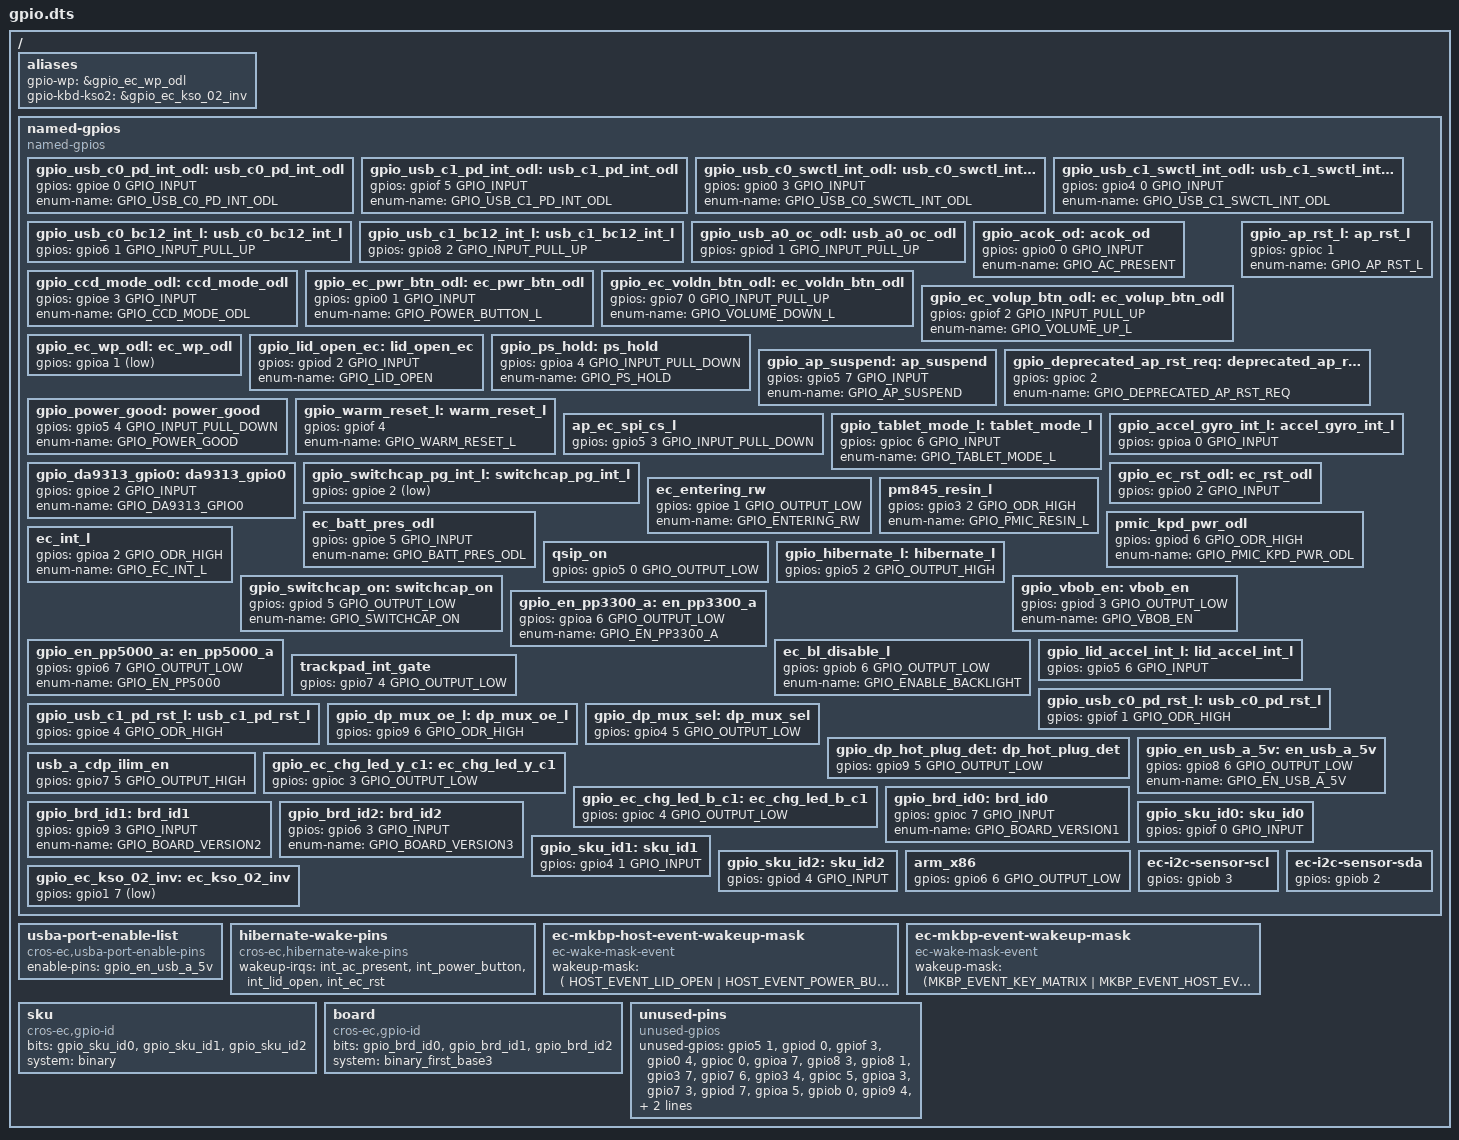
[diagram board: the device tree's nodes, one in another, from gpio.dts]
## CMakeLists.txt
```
# Copyright 2021 The ChromiumOS Authors
# Use of this source code is governed by a BSD-style license that can be
# found in the LICENSE file.

cmake_minimum_required(VERSION 3.13.1)

find_package(Zephyr REQUIRED HINTS "${ZEPHYR_BASE}")
project(lazor)

cros_ec_library_include_directories(include)

zephyr_library_sources_ifdef(CONFIG_PLATFORM_EC_USBC
  "src/power.c"
  "src/usb_pd_policy.c"
  "src/usbc_config.c")

zephyr_library_sources(
  "src/sku.c"
  "src/switchcap.c")

# Board specific implementation
zephyr_library_sources_ifdef(CONFIG_PLATFORM_EC_I2C
  "src/i2c.c")
```

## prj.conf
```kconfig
# Copyright 2021 The Chromium OS Authors. All rights reserved.
# Use of this source code is governed by a BSD-style license that can be
# found in the LICENSE file.

CONFIG_CROS_EC=y
#
# Lazor actually has a NPCX7M6FC, but
# the NPCX7M7FC is actually the same die, without the
# extra RAM being tested. The code size really could
# do with the extra space, so we pretend the EC is the
# part with the larger RAM. YMMV.
#
CONFIG_SOC_NPCX7M7FC=y
CONFIG_SOC_SERIES_NPCX7=y
CONFIG_SHIMMED_TASKS=y
CONFIG_PLATFORM_EC=y
CONFIG_PLATFORM_EC_BRINGUP=y
CONFIG_PLATFORM_EC_EXTPOWER_GPIO=y
CONFIG_PLATFORM_EC_SWITCH=y
CONFIG_PLATFORM_EC_LID_SWITCH=y
CONFIG_PLATFORM_EC_BACKLIGHT_LID=y
CONFIG_PLATFORM_EC_POWER_BUTTON=y

# I2C
CONFIG_I2C=y

# LED
CONFIG_PLATFORM_EC_LED_DT=y

# PWM
CONFIG_PWM=y
CONFIG_PWM_SHELL=n

# Application Processor is Qualcomm SC7180
CONFIG_AP_ARM_QUALCOMM_SC7180=y

# Board version is selected over GPIO board ID pins.
CONFIG_PLATFORM_EC_BOARD_VERSION_GPIO=y

# LN9310 Switchcap
CONFIG_PLATFORM_EC_SWITCHCAP_LN9310=y

# Power Sequencing
CONFIG_PLATFORM_EC_POWERSEQ=y
CONFIG_PLATFORM_EC_POWERSEQ_HOST_SLEEP=y
CONFIG_PLATFORM_EC_POWER_SLEEP_FAILURE_DETECTION=y
CONFIG_PLATFORM_EC_CHIPSET_RESET_HOOK=y
CONFIG_PLATFORM_EC_CHIPSET_RESUME_INIT_HOOK=y

# Trogdor family does not use EFS2
CONFIG_PLATFORM_EC_VBOOT_EFS2=n

# MKBP event
CONFIG_PLATFORM_EC_MKBP_EVENT=y
CONFIG_PLATFORM_EC_MKBP_USE_GPIO=y

# Keyboard
CONFIG_PLATFORM_EC_KEYBOARD=y
CONFIG_PLATFORM_EC_KEYBOARD_PROTOCOL_MKBP=y
CONFIG_PLATFORM_EC_MKBP_INPUT_DEVICES=y
CONFIG_PLATFORM_EC_KEYBOARD_COL2_INVERTED=y
CONFIG_PLATFORM_EC_VOLUME_BUTTONS=y
CONFIG_PLATFORM_EC_CMD_BUTTON=y
CONFIG_CROS_KB_RAW_NPCX=y

# ADC
CONFIG_ADC=y
CONFIG_ADC_SHELL=n

# Battery
CONFIG_PLATFORM_EC_BATTERY=y
CONFIG_PLATFORM_EC_BATTERY_SMART=y
CONFIG_PLATFORM_EC_I2C_VIRTUAL_BATTERY=y
CONFIG_PLATFORM_EC_I2C_PASSTHRU_RESTRICTED=y
CONFIG_PLATFORM_EC_BATTERY_FUEL_GAUGE=y
CONFIG_PLATFORM_EC_BATTERY_CUT_OFF=y
CONFIG_PLATFORM_EC_BATTERY_PRESENT_GPIO=y
CONFIG_PLATFORM_EC_CHARGER_ISL9238=y
CONFIG_PLATFORM_EC_CHARGE_RAMP_HW=y
CONFIG_PLATFORM_EC_USE_BATTERY_DEVICE_CHEMISTRY=y
CONFIG_PLATFORM_EC_BATTERY_DEVICE_CHEMISTRY="LION"
CONFIG_PLATFORM_EC_BATTERY_REVIVE_DISCONNECT=y
CONFIG_PLATFORM_EC_CHARGER_DISCHARGE_ON_AC=y
CONFIG_PLATFORM_EC_CHARGER_DISCHARGE_ON_AC_CHARGER=y
CONFIG_PLATFORM_EC_CHARGER_MIN_BAT_PCT_FOR_POWER_ON=2
CONFIG_PLATFORM_EC_CHARGER_MIN_POWER_MW_FOR_POWER_ON=10000
CONFIG_PLATFORM_EC_CHARGER_PROFILE_OVERRIDE=y
CONFIG_PLATFORM_EC_CHARGER_PSYS=y
CONFIG_PLATFORM_EC_CHARGER_PSYS_READ=y
CONFIG_PLATFORM_EC_CHARGER_SENSE_RESISTOR=10
CONFIG_PLATFORM_EC_CHARGER_SENSE_RESISTOR_AC=20
CONFIG_PLATFORM_EC_CONSOLE_CMD_CHARGER_ADC_AMON_BMON=y

# USB-A
CONFIG_PLATFORM_EC_USBA=y

# USB-C
CONFIG_PLATFORM_EC_BC12_DETECT_PI3USB9201=y
CONFIG_PLATFORM_EC_USB_PD_USB32_DRD=n
CONFIG_PLATFORM_EC_USBC_PPC_SN5S330=y
CONFIG_PLATFORM_EC_USBC_RETIMER_FW_UPDATE=n
CONFIG_PLATFORM_EC_USBC_SS_MUX_DFP_ONLY=y
CONFIG_PLATFORM_EC_USB_DRP_ACC_TRYSRC=y
CONFIG_PLATFORM_EC_USB_PD_5V_EN_CUSTOM=y
CONFIG_PLATFORM_EC_USB_PD_VBUS_DETECT_TCPC=y
CONFIG_PLATFORM_EC_USB_PD_DISCHARGE_PPC=y
CONFIG_PLATFORM_EC_USB_PD_REV30=n
CONFIG_PLATFORM_EC_USB_PD_TBT_COMPAT_MODE=n
CONFIG_PLATFORM_EC_USB_PD_USB4=n
CONFIG_PLATFORM_EC_USB_PD_TCPC_LOW_POWER=y
CONFIG_PLATFORM_EC_USB_PD_TCPM_MULTI_PS8XXX=y
CONFIG_PLATFORM_EC_USB_PD_TCPM_PS8751=y
CONFIG_PLATFORM_EC_USB_PD_TCPM_PS8805=y
CONFIG_PLATFORM_EC_USB_PD_TCPC_RUNTIME_CONFIG=n
CONFIG_PLATFORM_EC_USB_MUX_RUNTIME_CONFIG=n
CONFIG_PLATFORM_EC_USB_PD_LOGGING=y

# USB ID
# This is allocated specifically for Trogdor
# http://google3/hardware/standards/usb/
# TODO(b/183608112): Move to device tree
CONFIG_PLATFORM_EC_USB_PID=0x5043

# RTC
CONFIG_PLATFORM_EC_RTC=y
CONFIG_CROS_RTC_NPCX=y
CONFIG_PLATFORM_EC_HOSTCMD_RTC=y
CONFIG_PLATFORM_EC_CONSOLE_CMD_RTC=y

# EC software sync
CONFIG_PLATFORM_EC_VBOOT_HASH=y

# Sensors
CONFIG_PLATFORM_EC_MOTIONSENSE=y
CONFIG_PLATFORM_EC_ACCEL_FIFO=y
CONFIG_PLATFORM_EC_CONSOLE_CMD_ACCELS=y
CONFIG_PLATFORM_EC_CONSOLE_CMD_ACCEL_INFO=y
CONFIG_PLATFORM_EC_GMR_TABLET_MODE=y
CONFIG_PLATFORM_EC_LID_ANGLE=y
CONFIG_PLATFORM_EC_LID_ANGLE_UPDATE=y
CONFIG_PLATFORM_EC_SENSOR_TIGHT_TIMESTAMPS=y
CONFIG_PLATFORM_EC_TABLET_MODE=y
CONFIG_PLATFORM_EC_TABLET_MODE_SWITCH=y

# Sensor Drivers
CONFIG_PLATFORM_EC_ACCEL_BMA255=y
CONFIG_PLATFORM_EC_ACCELGYRO_BMI160=y
CONFIG_PLATFORM_EC_ACCELGYRO_BMI_COMM_I2C=y

# Console history
CONFIG_SHELL_HISTORY=y
CONFIG_SHELL_CMDS=y
CONFIG_SHELL_HELP=n
CONFIG_SHELL_MINIMAL=y

# Taskinfo
CONFIG_THREAD_MONITOR=y
CONFIG_KERNEL_SHELL=y

CONFIG_SYSCON=y

# Features should be enabled. But the code RAM is not enough, disable them.
#CONFIG_PLATFORM_EC_ACCEL_SPOOF_MODE=y
#CONFIG_PLATFORM_EC_EMULATED_SYSRQ=y
```

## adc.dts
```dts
/* Copyright 2022 The ChromiumOS Authors
 * Use of this source code is governed by a BSD-style license that can be
 * found in the LICENSE file.
 */

#include <zephyr/dt-bindings/adc/adc.h>

/ {
	named-adc-channels {
		compatible = "named-adc-channels";

		vbus {
			enum-name = "ADC_VBUS";
			io-channels = <&adc0 1>;
			/* Measure VBUS through a 1/10 voltage divider */
			mul = <10>;
		};
		amon_bmon {
			enum-name = "ADC_AMON_BMON";
			io-channels = <&adc0 2>;
			/*
			 * Adapter current output or battery charging/
			 * discharging current (uV) 18x amplification on
			 * charger side.
			 */
			mul = <1000>;
			div = <18>;
		};
		psys {
			enum-name = "ADC_PSYS";
			io-channels = <&adc0 3>;
			/*
			 * ISL9238 PSYS output is 1.44 uA/W over 5.6K resistor,
			 * to read 0.8V @ 99 W, i.e. 124000 uW/mV.
			 */
			mul = <124000>;
		};
	};

};

&adc0 {
	status = "okay";
	pinctrl-0 = <&adc0_chan1_gp44
		     &adc0_chan2_gp43
		     &adc0_chan3_gp42>;
	pinctrl-names = "default";
};
```

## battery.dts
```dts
/* Copyright 2021 The ChromiumOS Authors
 * Use of this source code is governed by a BSD-style license that can be
 * found in the LICENSE file.
 */

/ {
	batteries {
		default_battery: ap16l5j {
			compatible = "panasonic,ap16l5j", "battery-smart";
		};
		ap16l5j_009 {
			compatible = "panasonic,ap16l5j-009", "battery-smart";
		};
		ap16l8j {
			compatible = "lgc,ap16l8j", "battery-smart";
		};
		lgc_ap18c8k {
			compatible = "lgc,ap18c8k", "battery-smart";
		};
		murata_ap18c4k {
			compatible = "murata,ap18c4k", "battery-smart";
		};
	};
};
```

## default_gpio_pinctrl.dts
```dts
/* Copyright 2022 The ChromiumOS Authors
 * Use of this source code is governed by a BSD-style license that can be
 * found in the LICENSE file.
 */

/* Adds the &alt1_no_lpc_espi setting over the NPCX7 default setting. */
&{/def-io-conf-list} {
	pinmux = <&alt0_gpio_no_spip
		  &alt0_gpio_no_fpip
		  &alt1_no_pwrgd
		  &alt1_no_lpc_espi
		  &alta_no_peci_en
		  &altd_npsl_in1_sl
		  &altd_npsl_in2_sl
		  &altd_psl_in3_sl
		  &altd_psl_in4_sl
		  &alt7_no_ksi0_sl
		  &alt7_no_ksi1_sl
		  &alt7_no_ksi2_sl
		  &alt7_no_ksi3_sl
		  &alt7_no_ksi4_sl
		  &alt7_no_ksi5_sl
		  &alt7_no_ksi6_sl
		  &alt7_no_ksi7_sl
		  &alt8_no_kso00_sl
		  &alt8_no_kso01_sl
		  &alt8_no_kso02_sl
		  &alt8_no_kso03_sl
		  &alt8_no_kso04_sl
		  &alt8_no_kso05_sl
		  &alt8_no_kso06_sl
		  &alt8_no_kso07_sl
		  &alt9_no_kso08_sl
		  &alt9_no_kso09_sl
		  &alt9_no_kso10_sl
		  &alt9_no_kso11_sl
		  &alt9_no_kso12_sl
		  &alt9_no_kso13_sl
		  &alt9_no_kso14_sl
		  &alt9_no_kso15_sl
		  &alta_no_kso16_sl
		  &alta_no_kso17_sl >;
};
```

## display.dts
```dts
/* Copyright 2022 The Chromium OS Authors. All rights reserved.
 * Use of this source code is governed by a BSD-style license that can be
 * found in the LICENSE file.
 */

/ {
	displight {
		compatible = "cros-ec,displight";
		pwms = <&pwm5 0 PWM_HZ(4800) PWM_POLARITY_NORMAL>;
		generic-pwm-channel = <1>;
	};
};

&pwm5 {
	status = "okay";
	pinctrl-0 = <&pwm5_gpb7>;
	pinctrl-names = "default";
};
```

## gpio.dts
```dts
/* Copyright 2021 The Chromium OS Authors. All rights reserved.
 * Use of this source code is governed by a BSD-style license that can be
 * found in the LICENSE file.
 */

#include <dt-bindings/wake_mask_event_defines.h>

/ {
	aliases {
		gpio-wp = &gpio_ec_wp_odl;
		gpio-kbd-kso2 = &gpio_ec_kso_02_inv;
	};

	named-gpios {
		compatible = "named-gpios";

		gpio_usb_c0_pd_int_odl: usb_c0_pd_int_odl {
			gpios = <&gpioe 0 GPIO_INPUT>;
			enum-name = "GPIO_USB_C0_PD_INT_ODL";
		};
		gpio_usb_c1_pd_int_odl: usb_c1_pd_int_odl {
			gpios = <&gpiof 5 GPIO_INPUT>;
			enum-name = "GPIO_USB_C1_PD_INT_ODL";
		};
		gpio_usb_c0_swctl_int_odl: usb_c0_swctl_int_odl {
			gpios = <&gpio0 3 GPIO_INPUT>;
			enum-name = "GPIO_USB_C0_SWCTL_INT_ODL";
		};
		gpio_usb_c1_swctl_int_odl: usb_c1_swctl_int_odl {
			gpios = <&gpio4 0 GPIO_INPUT>;
			enum-name = "GPIO_USB_C1_SWCTL_INT_ODL";
		};
		gpio_usb_c0_bc12_int_l: usb_c0_bc12_int_l {
			gpios = <&gpio6 1 GPIO_INPUT_PULL_UP>;
		};
		gpio_usb_c1_bc12_int_l: usb_c1_bc12_int_l {
			gpios = <&gpio8 2 GPIO_INPUT_PULL_UP>;
		};
		gpio_usb_a0_oc_odl: usb_a0_oc_odl {
			gpios = <&gpiod 1 GPIO_INPUT_PULL_UP>;
		};
		gpio_acok_od: acok_od {
			gpios = <&gpio0 0 GPIO_INPUT>;
			enum-name = "GPIO_AC_PRESENT";
		};
		gpio_ccd_mode_odl: ccd_mode_odl {
			gpios = <&gpioe 3 GPIO_INPUT>;
			enum-name = "GPIO_CCD_MODE_ODL";
		};
		gpio_ec_pwr_btn_odl: ec_pwr_btn_odl {
			gpios = <&gpio0 1 GPIO_INPUT>;
			enum-name = "GPIO_POWER_BUTTON_L";
		};
		gpio_ec_voldn_btn_odl: ec_voldn_btn_odl {
			gpios = <&gpio7 0 GPIO_INPUT_PULL_UP>;
			enum-name = "GPIO_VOLUME_DOWN_L";
		};
		gpio_ec_volup_btn_odl: ec_volup_btn_odl {
			gpios = <&gpiof 2 GPIO_INPUT_PULL_UP>;
			enum-name = "GPIO_VOLUME_UP_L";
		};
		gpio_ec_wp_odl: ec_wp_odl {
			gpios = <&gpioa 1 (GPIO_INPUT | GPIO_ACTIVE_LOW)>;
		};
		gpio_lid_open_ec: lid_open_ec {
			gpios = <&gpiod 2 GPIO_INPUT>;
			enum-name = "GPIO_LID_OPEN";
		};
		gpio_ap_rst_l: ap_rst_l {
			gpios = <&gpioc 1 (GPIO_INPUT | GPIO_VOLTAGE_1P8)>;
			enum-name = "GPIO_AP_RST_L";
		};
		gpio_ps_hold: ps_hold {
			gpios = <&gpioa 4 GPIO_INPUT_PULL_DOWN>;
			enum-name = "GPIO_PS_HOLD";
		};
		gpio_ap_suspend: ap_suspend {
			gpios = <&gpio5 7 GPIO_INPUT>;
			enum-name = "GPIO_AP_SUSPEND";
		};
		gpio_deprecated_ap_rst_req: deprecated_ap_rst_req {
			gpios = <&gpioc 2 (GPIO_INPUT_PULL_DOWN | GPIO_VOLTAGE_1P8)>;
			enum-name = "GPIO_DEPRECATED_AP_RST_REQ";
		};
		gpio_power_good: power_good {
			gpios = <&gpio5 4 GPIO_INPUT_PULL_DOWN>;
			enum-name = "GPIO_POWER_GOOD";
		};
		gpio_warm_reset_l: warm_reset_l {
			gpios = <&gpiof 4 (GPIO_INPUT | GPIO_VOLTAGE_1P8)>;
			enum-name = "GPIO_WARM_RESET_L";
		};
		ap_ec_spi_cs_l {
			gpios = <&gpio5 3 GPIO_INPUT_PULL_DOWN>;
		};
		gpio_tablet_mode_l: tablet_mode_l {
			gpios = <&gpioc 6 GPIO_INPUT>;
			enum-name = "GPIO_TABLET_MODE_L";
		};
		gpio_accel_gyro_int_l: accel_gyro_int_l {
			gpios = <&gpioa 0 GPIO_INPUT>;
		};
		gpio_da9313_gpio0: da9313_gpio0 {
			gpios = <&gpioe 2 GPIO_INPUT>;
			enum-name = "GPIO_DA9313_GPIO0";
		};
		/*
		 * Active low input
		 */
		gpio_switchcap_pg_int_l: switchcap_pg_int_l {
			gpios = <&gpioe 2 (GPIO_ACTIVE_LOW | GPIO_INPUT)>;
		};
		gpio_ec_rst_odl: ec_rst_odl {
			gpios = <&gpio0 2 GPIO_INPUT>;
		};
		ec_entering_rw {
			gpios = <&gpioe 1 GPIO_OUTPUT_LOW>;
			enum-name = "GPIO_ENTERING_RW";
		};
		ec_batt_pres_odl {
			gpios = <&gpioe 5 GPIO_INPUT>;
			enum-name = "GPIO_BATT_PRES_ODL";
		};
		pm845_resin_l {
			gpios = <&gpio3 2 GPIO_ODR_HIGH>;
			enum-name = "GPIO_PMIC_RESIN_L";
		};
		pmic_kpd_pwr_odl {
			gpios = <&gpiod 6 GPIO_ODR_HIGH>;
			enum-name = "GPIO_PMIC_KPD_PWR_ODL";
		};
		ec_int_l {
			gpios = <&gpioa 2 GPIO_ODR_HIGH>;
			enum-name = "GPIO_EC_INT_L";
		};
		qsip_on {
			gpios = <&gpio5 0 GPIO_OUTPUT_LOW>;
		};
		gpio_hibernate_l: hibernate_l {
			gpios = <&gpio5 2 GPIO_OUTPUT_HIGH>;
		};
		gpio_switchcap_on: switchcap_on {
			gpios = <&gpiod 5 GPIO_OUTPUT_LOW>;
			enum-name = "GPIO_SWITCHCAP_ON";
		};
		gpio_vbob_en: vbob_en {
			gpios = <&gpiod 3 GPIO_OUTPUT_LOW>;
			enum-name = "GPIO_VBOB_EN";
		};
		gpio_en_pp3300_a: en_pp3300_a {
			gpios = <&gpioa 6 GPIO_OUTPUT_LOW>;
			enum-name = "GPIO_EN_PP3300_A";
		};
		gpio_en_pp5000_a: en_pp5000_a {
			gpios = <&gpio6 7 GPIO_OUTPUT_LOW>;
			enum-name = "GPIO_EN_PP5000";
		};
		ec_bl_disable_l {
			gpios = <&gpiob 6 GPIO_OUTPUT_LOW>;
			enum-name = "GPIO_ENABLE_BACKLIGHT";
		};
		gpio_lid_accel_int_l: lid_accel_int_l {
			gpios = <&gpio5 6 GPIO_INPUT>;
		};
		trackpad_int_gate {
			gpios = <&gpio7 4 GPIO_OUTPUT_LOW>;
		};
		gpio_usb_c0_pd_rst_l: usb_c0_pd_rst_l {
			gpios = <&gpiof 1 GPIO_ODR_HIGH>;
		};
		gpio_usb_c1_pd_rst_l: usb_c1_pd_rst_l {
			gpios = <&gpioe 4 GPIO_ODR_HIGH>;
		};
		gpio_dp_mux_oe_l: dp_mux_oe_l {
			gpios = <&gpio9 6 GPIO_ODR_HIGH>;
		};
		gpio_dp_mux_sel: dp_mux_sel {
			gpios = <&gpio4 5 GPIO_OUTPUT_LOW>;
		};
		gpio_dp_hot_plug_det: dp_hot_plug_det {
			gpios = <&gpio9 5 GPIO_OUTPUT_LOW>;
		};
		gpio_en_usb_a_5v: en_usb_a_5v {
			gpios = <&gpio8 6 GPIO_OUTPUT_LOW>;
			enum-name = "GPIO_EN_USB_A_5V";
		};
		usb_a_cdp_ilim_en {
			gpios = <&gpio7 5 GPIO_OUTPUT_HIGH>;
		};
		gpio_ec_chg_led_y_c1: ec_chg_led_y_c1 {
			#led-pin-cells = <1>;
			gpios = <&gpioc 3 GPIO_OUTPUT_LOW>;
		};
		gpio_ec_chg_led_b_c1: ec_chg_led_b_c1 {
			#led-pin-cells = <1>;
			gpios = <&gpioc 4 GPIO_OUTPUT_LOW>;
		};
		gpio_brd_id0: brd_id0 {
			gpios = <&gpioc 7 GPIO_INPUT>;
			enum-name = "GPIO_BOARD_VERSION1";
		};
		gpio_brd_id1: brd_id1 {
			gpios = <&gpio9 3 GPIO_INPUT>;
			enum-name = "GPIO_BOARD_VERSION2";
		};
		gpio_brd_id2: brd_id2 {
			gpios = <&gpio6 3 GPIO_INPUT>;
			enum-name = "GPIO_BOARD_VERSION3";
		};
		gpio_sku_id0: sku_id0 {
			gpios = <&gpiof 0 GPIO_INPUT>;
		};
		gpio_sku_id1: sku_id1 {
			gpios = <&gpio4 1 GPIO_INPUT>;
		};
		gpio_sku_id2: sku_id2 {
			gpios = <&gpiod 4 GPIO_INPUT>;
		};
		arm_x86 {
			gpios = <&gpio6 6 GPIO_OUTPUT_LOW>;
		};
		ec-i2c-sensor-scl {
			gpios = <&gpiob 3 (GPIO_INPUT | GPIO_VOLTAGE_1P8)>;
		};
		ec-i2c-sensor-sda {
			gpios = <&gpiob 2 (GPIO_INPUT | GPIO_VOLTAGE_1P8)>;
		};
		gpio_ec_kso_02_inv: ec_kso_02_inv {
			gpios = <&gpio1 7 (GPIO_OUTPUT_LOW | GPIO_ACTIVE_LOW)>;
		};
	};

	usba-port-enable-list {
		compatible = "cros-ec,usba-port-enable-pins";
		enable-pins = <&gpio_en_usb_a_5v>;
	};

	hibernate-wake-pins {
		compatible = "cros-ec,hibernate-wake-pins";
		wakeup-irqs = <
			&int_ac_present
			&int_power_button
			&int_lid_open
			&int_ec_rst
		>;
	};

	ec-mkbp-host-event-wakeup-mask {
		compatible = "ec-wake-mask-event";
		wakeup-mask = <(
			HOST_EVENT_LID_OPEN |
			HOST_EVENT_POWER_BUTTON |
			HOST_EVENT_AC_CONNECTED |
			HOST_EVENT_AC_DISCONNECTED |
			HOST_EVENT_HANG_DETECT |
			HOST_EVENT_RTC |
			HOST_EVENT_MODE_CHANGE |
			HOST_EVENT_DEVICE)>;
	};

	ec-mkbp-event-wakeup-mask {
		compatible = "ec-wake-mask-event";
		wakeup-mask = <(MKBP_EVENT_KEY_MATRIX |
				MKBP_EVENT_HOST_EVENT |
				MKBP_EVENT_SENSOR_FIFO)>;
	};

	sku {
		compatible = "cros-ec,gpio-id";

		bits  = <
			&gpio_sku_id0
			&gpio_sku_id1
			&gpio_sku_id2
		>;

		system = "binary";
	};

	board {
		compatible = "cros-ec,gpio-id";

		bits  = <
			&gpio_brd_id0
			&gpio_brd_id1
			&gpio_brd_id2
		>;

		system = "binary_first_base3";
	};

	unused-pins {
		compatible = "unused-gpios";
		unused-gpios =
			<&gpio5 1 0>,
			<&gpiod 0 0>,
			<&gpiof 3 0>,
			<&gpio0 4 0>,
			<&gpioc 0 0>,
			<&gpioa 7 0>,
			<&gpio8 3 0>,
			<&gpio8 1 0>,
			<&gpio3 7 0>,
			<&gpio7 6 0>,
			<&gpio3 4 0>,
			<&gpioc 5 0>,
			<&gpioa 3 0>,
			<&gpio7 3 0>,
			<&gpiod 7 0>,
			<&gpioa 5 0>,
			<&gpiob 0 0>,
			<&gpio9 4 0>,
			<&gpiob 1 0>,
			<&gpio6 2 0>,
			<&gpio3 5 0>,
			<&gpio9 7 0>,
			<&gpio6 0 0>,
			<&gpio7 2 0>;
	};
};
```

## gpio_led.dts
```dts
/* Copyright 2022 The ChromiumOS Authors
 * Use of this source code is governed by a BSD-style license that can be
 * found in the LICENSE file.
 */

/ {
	gpio-led-pins {
		compatible = "cros-ec,gpio-led-pins";

		color_off: color-off {
			led-color = "LED_OFF";
			led-id = "EC_LED_ID_BATTERY_LED";
			led-pins = <&gpio_ec_chg_led_y_c1 0>,
				   <&gpio_ec_chg_led_b_c1 0>;
		};

		color_amber: color-amber {
			led-color = "LED_AMBER";
			led-id = "EC_LED_ID_BATTERY_LED";
			br-color = "EC_LED_COLOR_AMBER";
			led-pins = <&gpio_ec_chg_led_y_c1 1>,
				   <&gpio_ec_chg_led_b_c1 0>;
		};

		color_blue: color-blue {
			led-color = "LED_BLUE";
			led-id = "EC_LED_ID_BATTERY_LED";
			br-color = "EC_LED_COLOR_BLUE";
			led-pins = <&gpio_ec_chg_led_y_c1 0>,
				   <&gpio_ec_chg_led_b_c1 1>;
		};
	};
};
```

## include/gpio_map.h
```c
/* Copyright 2021 The Chromium OS Authors. All rights reserved.
 * Use of this source code is governed by a BSD-style license that can be
 * found in the LICENSE file.
 */

#ifndef __ZEPHYR_GPIO_MAP_H
#define __ZEPHYR_GPIO_MAP_H

#include <devicetree.h>
#include <gpio_signal.h>

/*
 * Set EC_CROS_GPIO_INTERRUPTS to a space-separated list of GPIO_INT items.
 *
 * Each GPIO_INT requires three parameters:
 *   gpio_signal - The enum gpio_signal for the interrupt gpio
 *   interrupt_flags - The interrupt-related flags (e.g. GPIO_INT_EDGE_BOTH)
 *   handler - The platform/ec interrupt handler.
 *
 * Ensure that this files includes all necessary headers to declare all
 * referenced handler functions.
 *
 * For example, one could use the follow definition:
 * #define EC_CROS_GPIO_INTERRUPTS \
 *   GPIO_INT(NAMED_GPIO(h1_ec_pwr_btn_odl), GPIO_INT_EDGE_BOTH, button_print)
 */
#define EC_CROS_GPIO_INTERRUPTS                                               \
	GPIO_INT(GPIO_AC_PRESENT, GPIO_INT_EDGE_BOTH, extpower_interrupt)     \
	GPIO_INT(GPIO_LID_OPEN, GPIO_INT_EDGE_BOTH, lid_interrupt)            \
	GPIO_INT(GPIO_WP_L, GPIO_INT_EDGE_BOTH, switch_interrupt)             \
	GPIO_INT(GPIO_POWER_BUTTON_L, GPIO_INT_EDGE_BOTH,                     \
		 power_button_interrupt)                                      \
	GPIO_INT(GPIO_VOLUME_DOWN_L, GPIO_INT_EDGE_BOTH, button_interrupt)    \
	GPIO_INT(GPIO_VOLUME_UP_L, GPIO_INT_EDGE_BOTH, button_interrupt)      \
	GPIO_INT(GPIO_SWITCHCAP_PG_INT_L, GPIO_INT_EDGE_FALLING,              \
		 ln9310_interrupt)                                            \
	GPIO_INT(GPIO_AP_RST_L, GPIO_INT_EDGE_BOTH, chipset_ap_rst_interrupt) \
	GPIO_INT(GPIO_AP_SUSPEND, GPIO_INT_EDGE_BOTH, power_signal_interrupt) \
	GPIO_INT(GPIO_DEPRECATED_AP_RST_REQ, GPIO_INT_EDGE_BOTH,              \
		 power_signal_interrupt)                                      \
	GPIO_INT(GPIO_POWER_GOOD, GPIO_INT_EDGE_BOTH,                         \
		 chipset_power_good_interrupt)                                \
	GPIO_INT(GPIO_PS_HOLD, GPIO_INT_EDGE_BOTH, power_signal_interrupt)    \
	GPIO_INT(GPIO_WARM_RESET_L, GPIO_INT_EDGE_BOTH,                       \
		 chipset_warm_reset_interrupt)                                \
	GPIO_INT(GPIO_USB_C0_PD_INT_ODL, GPIO_INT_EDGE_FALLING,               \
		 tcpc_alert_event)                                            \
	GPIO_INT(GPIO_USB_C1_PD_INT_ODL, GPIO_INT_EDGE_FALLING,               \
		 tcpc_alert_event)                                            \
	GPIO_INT(GPIO_USB_C0_SWCTL_INT_ODL, GPIO_INT_EDGE_FALLING,            \
		 ppc_interrupt)                                               \
	GPIO_INT(GPIO_USB_C1_SWCTL_INT_ODL, GPIO_INT_EDGE_FALLING,            \
		 ppc_interrupt)                                               \
	GPIO_INT(GPIO_USB_C0_BC12_INT_L, GPIO_INT_EDGE_FALLING, usb0_evt)     \
	GPIO_INT(GPIO_USB_C1_BC12_INT_L, GPIO_INT_EDGE_FALLING, usb1_evt)     \
	GPIO_INT(GPIO_USB_A0_OC_ODL, GPIO_INT_EDGE_BOTH, usba_oc_interrupt)   \
	GPIO_INT(GPIO_CCD_MODE_ODL, GPIO_INT_EDGE_FALLING,                    \
		 board_connect_c0_sbu)                                        \
	GPIO_INT(GPIO_ACCEL_GYRO_INT_L, GPIO_INT_EDGE_FALLING,                \
		 bmi160_interrupt)                                            \
	GPIO_INT(GPIO_TABLET_MODE_L, GPIO_INT_EDGE_BOTH, gmr_tablet_switch_isr)

#endif /* __ZEPHYR_GPIO_MAP_H */
```

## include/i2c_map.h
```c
/* Copyright 2021 The Chromium OS Authors. All rights reserved.
 * Use of this source code is governed by a BSD-style license that can be
 * found in the LICENSE file.
 */

#ifndef __ZEPHYR_I2C_MAP_H
#define __ZEPHYR_I2C_MAP_H

#include <devicetree.h>

#include "i2c/i2c.h"

#define I2C_PORT_BATTERY	I2C_PORT_POWER
#define I2C_PORT_VIRTUAL	I2C_PORT_BATTERY
#define I2C_PORT_CHARGER	I2C_PORT_POWER
#define I2C_PORT_ACCEL		I2C_PORT_SENSOR

#define I2C_PORT_POWER		NAMED_I2C(power)
#define I2C_PORT_TCPC0		NAMED_I2C(tcpc0)
#define I2C_PORT_TCPC1		NAMED_I2C(tcpc1)
#define I2C_PORT_WLC		NAMED_I2C(wlc)
#define I2C_PORT_EEPROM		NAMED_I2C(eeprom)
#define I2C_PORT_SENSOR		NAMED_I2C(sensor)

#endif /* __ZEPHYR_I2C_MAP_H */
```

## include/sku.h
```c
/* Copyright 2022 The Chromium OS Authors. All rights reserved.
 * Use of this source code is governed by a BSD-style license that can be
 * found in the LICENSE file.
 */

/* Lazor board-specific SKU configuration */

#ifndef __ZEPHYR_LAZOR_SKU_H
#define __ZEPHYR_LAZOR_SKU_H

int board_get_version(void);
int board_is_clamshell(void);
int board_has_da9313(void);
int board_has_ln9310(void);
int board_has_buck_ic(void);

#endif /* __ZEPHYR_LAZOR_SKU_H */
```

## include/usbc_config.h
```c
/* Copyright 2022 The Chromium OS Authors. All rights reserved.
 * Use of this source code is governed by a BSD-style license that can be
 * found in the LICENSE file.
 */

/* lazor board-specific USB-C configuration */

#ifndef __ZEPHYR_LAZOR_USBC_CONFIG_H
#define __ZEPHYR_LAZOR_USBC_CONFIG_H

#include "gpio.h"

void tcpc_alert_event(enum gpio_signal signal);
void usb0_evt(enum gpio_signal signal);
void usb1_evt(enum gpio_signal signal);
void usba_oc_interrupt(enum gpio_signal signal);
void ppc_interrupt(enum gpio_signal signal);
void board_connect_c0_sbu(enum gpio_signal s);

#endif /* __ZEPHYR_LAZOR_USBC_CONFIG_H */
```

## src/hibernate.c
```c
/* Copyright 2022 The Chromium OS Authors. All rights reserved.
 * Use of this source code is governed by a BSD-style license that can be
 * found in the LICENSE file.
 */

#include "common.h"
#include "sku.h"
#include "system.h"
#include "usbc_ppc.h"

void board_hibernate(void)
{
	int i;

	if (!board_is_clamshell()) {
		/*
		 * Sensors are unpowered in hibernate. Apply PD to the
		 * interrupt lines such that they don't float.
		 */
		gpio_pin_configure_dt(
			GPIO_DT_FROM_NODELABEL(gpio_accel_gyro_int_l),
			GPIO_DISCONNECTED);
		gpio_pin_configure_dt(
			GPIO_DT_FROM_NODELABEL(gpio_lid_accel_int_l),
			GPIO_DISCONNECTED);
	}

	/*
	 * Board rev 5+ has the hardware fix. Don't need the following
	 * workaround.
	 */
	if (system_get_board_version() >= 5)
		return;

	/*
	 * Enable the PPC power sink path before EC enters hibernate;
	 * otherwise, ACOK won't go High and can't wake EC up. Check the
	 * bug b/170324206 for details.
	 */
	for (i = 0; i < CONFIG_USB_PD_PORT_MAX_COUNT; i++)
		ppc_vbus_sink_enable(i, 1);
}

void board_hibernate_late(void)
{
	/* Set the hibernate GPIO to turn off the rails */
	gpio_pin_set_dt(GPIO_DT_FROM_NODELABEL(gpio_hibernate_l), 0);
}
```

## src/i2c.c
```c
/* Copyright 2021 The Chromium OS Authors. All rights reserved.
 * Use of this source code is governed by a BSD-style license that can be
 * found in the LICENSE file.
 */

#include "i2c/i2c.h"
#include "i2c.h"

/* Lazor board specific i2c implementation */

#ifdef CONFIG_PLATFORM_EC_I2C_PASSTHRU_RESTRICTED
int board_allow_i2c_passthru(const struct i2c_cmd_desc_t *cmd_desc)
{
	return (i2c_get_device_for_port(cmd_desc->port) ==
		i2c_get_device_for_port(I2C_PORT_VIRTUAL_BATTERY));
}
#endif
```

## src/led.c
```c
/* Copyright 2022 The Chromium OS Authors. All rights reserved.
 * Use of this source code is governed by a BSD-style license that can be
 * found in the LICENSE file.
 *
 * Power and battery LED control.
 */

#include <drivers/gpio.h>

#include "battery.h"
#include "charge_manager.h"
#include "charge_state.h"
#include "chipset.h"
#include "ec_commands.h"
#include "hooks.h"
#include "host_command.h"
#include "led_common.h"
#include "power.h"
#include "system.h"
#include "util.h"

#include <devicetree.h>
#include <logging/log.h>
LOG_MODULE_REGISTER(gpio_led, LOG_LEVEL_ERR);

#define LED_ONE_SEC (1000 / HOOK_TICK_INTERVAL_MS)

#define BAT_LED_ON 1
#define BAT_LED_OFF 0

#define GPIO_LED_COLOR_NODE  DT_PATH(gpio_led, gpio_led_colors)
#define GPIO_LED_PINS_NODE   DT_PATH(gpio_led, gpio_led_pins)

const enum ec_led_id supported_led_ids[] = {
	EC_LED_ID_BATTERY_LED,
};

const int supported_led_ids_count = ARRAY_SIZE(supported_led_ids);

enum led_color {
	LED_OFF = 0,
	LED_AMBER,
	LED_BLUE,
	LED_COLOR_COUNT  /* Number of colors, not a color itself */
};

#define LED_PIN_COUNT	(LED_COLOR_COUNT - 1)

struct led_color_node_t {
	int led_color;
	int acc_period;
};

enum led_extra_flag_t {
	NONE = 0,
	LED_CHFLAG_FORCE_IDLE,
	LED_CHFLAG_DEFAULT,
	LED_BATT_BELOW_10_PCT,
	LED_BATT_ABOVE_10_PCT,
};

/*
 * Currently 4 different colors are supported for blinking LED, each of which
 * can have different periods. Each period slot is the accumulation of previous
 * periods as described below. Last slot is the total accumulation which is
 * used as a dividing factor to calculate ticks to switch color
 * Eg LED_COLOR_1 1 sec, LED_COLOR_2 2 sec, LED_COLOR_3 3 sec, LED_COLOR_4 3 sec
 * period_1 = 1, period_2 = 1 + 2, period_3 = 1 + 2 + 3, period_4 =1 + 2 + 3 + 3
 * ticks -> 0, 1, 2, 3, 4, 5, 6, 7, 8, 0, 1, 2 and so on (ticks % 9)
 * 0 < period_1 -> LED_COLOR_1 for 1 sec
 * 1, 2 < period_2 -> LED_COLOR_2 for 2 secs
 * 3, 4, 5 < period_3 -> LED_COLOR_3 for 3 secs
 * 6, 7, 8 < period_4 -> LED_COLOR_4 for 3 secs
 */
#define MAX_COLOR	4

struct node_prop_t {
	enum charge_state pwr_state;
	enum power_state chipset_state;
	enum led_extra_flag_t led_extra_flag;
	struct led_color_node_t led_colors[MAX_COLOR];
};

/*
 * acc_period is the accumulated period value of all color-x children
 * led_colors[0].acc_period = period value of color-0 node
 * led_colors[1].acc_period = period value of color-0 + color-1 nodes
 * led_colors[2].acc_period = period value of color-0 + color-1 + color-2 nodes
 * and so on. If period prop or color node doesn't exist, period val is 0
 */

#define PERIOD_VAL(id) COND_CODE_1(DT_NODE_HAS_PROP(id, period),	\
				   (DT_PROP(id, period)),		\
				   (0))

#define LED_PERIOD(color_num, state_id)					\
	PERIOD_VAL(DT_CHILD(state_id, color_##color_num))

#define LED_PLUS_PERIOD(color_num, state_id)				\
	+ LED_PERIOD(color_num, state_id)

#define ACC_PERIOD(color_num, state_id)					\
	(0 LISTIFY(color_num, LED_PLUS_PERIOD, (), state_id))

#define GET_PROP(id, prop)						\
	COND_CODE_1(DT_NODE_HAS_PROP(id, prop),				\
		    (DT_STRING_UPPER_TOKEN(id, prop)),			\
		    (0))

#define LED_COLOR_INIT(color_num, color_num_plus_one, state_id)		\
{									\
	.led_color = GET_PROP(DT_CHILD(state_id, color_##color_num),	\
							led_color),	\
	.acc_period = ACC_PERIOD(color_num_plus_one, state_id)		\
}

/* Initialize node_array struct with prop listed in dts */
#define SET_LED_VALUES(state_id)					\
{									\
	.pwr_state = GET_PROP(state_id, charge_state),			\
	.chipset_state = GET_PROP(state_id, chipset_state),		\
	.led_extra_flag = GET_PROP(state_id, extra_flag),		\
	.led_colors = {LED_COLOR_INIT(0, 1, state_id),			\
		       LED_COLOR_INIT(1, 2, state_id),			\
		       LED_COLOR_INIT(2, 3, state_id),			\
		       LED_COLOR_INIT(3, 4, state_id),			\
		      }							\
},

struct node_prop_t node_array[] = {
	DT_FOREACH_CHILD(GPIO_LED_COLOR_NODE, SET_LED_VALUES)
};

struct gpio_pins_t {
	enum gpio_signal signal;
	int val;
};

struct led_pins_node_t {
	int led_color;
	struct gpio_pins_t gpio_pins[LED_PIN_COUNT];
};

#define SET_PIN(node_id, prop, i)					\
{									\
	.signal = GPIO_SIGNAL(DT_PHANDLE_BY_IDX(node_id, prop, i)),	\
	.val = DT_PHA_BY_IDX(node_id, prop, i, value)			\
},

#define SET_GPIO_PIN(node_id)						\
{									\
	DT_FOREACH_PROP_ELEM(node_id, led_pins, SET_PIN)		\
}

#define SET_PIN_NODE(node_id)						\
{									\
	.led_color = GET_PROP(node_id, led_color),			\
	.gpio_pins = SET_GPIO_PIN(node_id)				\
},

struct led_pins_node_t pins_node[LED_COLOR_COUNT] = {
	DT_FOREACH_CHILD(GPIO_LED_PINS_NODE, SET_PIN_NODE)
};

static void led_set_color(enum led_color color)
{
	for (int i = 0; i < LED_COLOR_COUNT; i++) {
		if (pins_node[i].led_color == color) {
			for (int j = 0; j < LED_PIN_COUNT; j++) {
				gpio_pin_set_dt(gpio_get_dt_spec(
					pins_node[i].gpio_pins[j].signal),
					pins_node[i].gpio_pins[j].val);
			}
		}
	}
}

void led_get_brightness_range(enum ec_led_id led_id, uint8_t *brightness_range)
{
	brightness_range[EC_LED_COLOR_AMBER] = 1;
	brightness_range[EC_LED_COLOR_BLUE] = 1;
}

int led_set_brightness(enum ec_led_id led_id, const uint8_t *brightness)
{
	if (brightness[EC_LED_COLOR_BLUE] != 0)
		led_set_color(LED_BLUE);
	else if (brightness[EC_LED_COLOR_AMBER] != 0)
		led_set_color(LED_AMBER);
	else
		led_set_color(LED_OFF);

	return EC_SUCCESS;
}

static enum power_state get_chipset_state(void)
{
	enum power_state chipset_state = 0;

	/*
	 * Only covers subset of power states as other states don't
	 * alter LED behavior
	 */
	if (chipset_in_state(CHIPSET_STATE_ON))
		/* S0 */
		chipset_state = POWER_S0;
	else if (chipset_in_state(CHIPSET_STATE_ANY_SUSPEND))
		/* S3 */
		chipset_state = POWER_S3;
	else if (chipset_in_state(CHIPSET_STATE_ANY_OFF))
		/* S5 */
		chipset_state = POWER_S5;

	return chipset_state;
}

static bool find_node_with_extra_flag(int i)
{
	uint32_t chflags = charge_get_flags();
	bool found_node = false;

	switch (node_array[i].led_extra_flag) {
	case LED_CHFLAG_FORCE_IDLE:
	case LED_CHFLAG_DEFAULT:
		if (chflags & CHARGE_FLAG_FORCE_IDLE) {
			if (node_array[i].led_extra_flag ==
					LED_CHFLAG_FORCE_IDLE)
				found_node = true;
		} else {
			if (node_array[i].led_extra_flag == LED_CHFLAG_DEFAULT)
				found_node = true;
		}
		break;
	case LED_BATT_BELOW_10_PCT:
	case LED_BATT_ABOVE_10_PCT:
		if (charge_get_percent() < 10) {
			if (node_array[i].led_extra_flag ==
					LED_BATT_BELOW_10_PCT)
				found_node = true;
		} else {
			if (node_array[i].led_extra_flag !=
					LED_BATT_ABOVE_10_PCT)
				found_node = true;
		}
		break;
	default:
		LOG_ERR("Invalid led extra flag %d",
				node_array[i].led_extra_flag);
		break;
	}

	return found_node;
}

static int find_node(void)
{
	int i = 0;

	for (i = 0; i < ARRAY_SIZE(node_array); i++) {
		/* Check if this node depends on power state */
		if (node_array[i].pwr_state != PWR_STATE_UNCHANGE) {
			enum charge_state pwr_state = charge_get_state();

			if (node_array[i].pwr_state != pwr_state)
				continue;
		}

		/* Check if this node depends on chipset state */
		if (node_array[i].chipset_state != 0) {
			enum power_state chipset_state =
						get_chipset_state();

			/* Continue at current index as nodes are in sequence */
			if (node_array[i].chipset_state != chipset_state)
				continue;
		}

		/* Check if the node depends on any special flags */
		if (node_array[i].led_extra_flag != NONE)
			if (!find_node_with_extra_flag(i))
				continue;

		/* We found the node */
		return i;
	}

	/*
	 * Didn't find a valid node that matches all the properties
	 * Return -1 to signify error
	 */
	return -1;
}

#define GET_PERIOD(n_idx, c_idx)  node_array[n_idx].led_colors[c_idx].acc_period
#define GET_COLOR(n_idx, c_idx)   node_array[n_idx].led_colors[c_idx].led_color

static int find_color(int node_idx, int ticks)
{
	int color_idx = 0;

	/* If period value at index 0 is not 0, it's a blinking LED */
	if (GET_PERIOD(node_idx, 0) != 0) {
		/*  Period is accumulated at the last index */
		ticks = ticks % GET_PERIOD(node_idx, MAX_COLOR - 1);

		for (color_idx = 0; color_idx < MAX_COLOR; color_idx++) {
			if (ticks < GET_PERIOD(node_idx, color_idx))
				break;
		}
	}

	return GET_COLOR(node_idx, color_idx);
}

static void board_led_set_color(void)
{
	int color = LED_OFF;
	int node = 0;
	static int ticks;

	ticks++;

	node = find_node();

	if (node < 0)
		LOG_ERR("Invalid node id, node with matching prop not found");
	else
		color = find_color(node, ticks);

	led_set_color(color);
}

/* Called by hook task every second */
static void led_tick(void)
{
	if (led_auto_control_is_enabled(EC_LED_ID_BATTERY_LED))
		board_led_set_color();
}
DECLARE_HOOK(HOOK_SECOND, led_tick, HOOK_PRIO_DEFAULT);

void led_control(enum ec_led_id led_id, enum ec_led_state state)
{
	enum led_color color;

	if ((led_id != EC_LED_ID_RECOVERY_HW_REINIT_LED) &&
	    (led_id != EC_LED_ID_SYSRQ_DEBUG_LED))
		return;

	if (state == LED_STATE_RESET) {
		led_auto_control(EC_LED_ID_BATTERY_LED, 1);
		board_led_set_color();
		return;
	}

	color = state ? LED_BLUE : LED_OFF;

	led_auto_control(EC_LED_ID_BATTERY_LED, 0);

	led_set_color(color);
}
```

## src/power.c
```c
/* Copyright 2022 The ChromiumOS Authors
 * Use of this source code is governed by a BSD-style license that can be
 * found in the LICENSE file.
 */

#include <zephyr/init.h>
#include <zephyr/drivers/gpio.h>

#include <ap_power/ap_power.h>
#include "power.h"
#include "task.h"
#include "gpio.h"

static void board_power_change(struct ap_power_ev_callback *cb,
			       struct ap_power_ev_data data)
{
	switch (data.event) {
	default:
		return;

	case AP_POWER_PRE_INIT:
		/* Turn on the 3.3V rail */
		gpio_pin_set_dt(GPIO_DT_FROM_NODELABEL(gpio_en_pp3300_a), 1);

		/* Turn on the 5V rail. */
#ifdef CONFIG_POWER_PP5000_CONTROL
		power_5v_enable(task_get_current(), 1);
#else /* !defined(CONFIG_POWER_PP5000_CONTROL) */
		gpio_pin_set_dt(GPIO_DT_FROM_NODELABEL(gpio_en_pp5000_a), 1);
#endif /* defined(CONFIG_POWER_PP5000_CONTROL) */
		break;

	case AP_POWER_SHUTDOWN_COMPLETE:
		/* Turn off the 5V rail. */
#ifdef CONFIG_POWER_PP5000_CONTROL
		power_5v_enable(task_get_current(), 0);
#else /* !defined(CONFIG_POWER_PP5000_CONTROL) */
		gpio_pin_set_dt(GPIO_DT_FROM_NODELABEL(gpio_en_pp5000_a), 0);
#endif /* defined(CONFIG_POWER_PP5000_CONTROL) */

		/* Turn off the 3.3V and 5V rails. */
		gpio_pin_set_dt(GPIO_DT_FROM_NODELABEL(gpio_en_pp3300_a), 0);
		break;
	}
}

static int board_power_handler_init(const struct device *unused)
{
	static struct ap_power_ev_callback cb;

	/* Setup a suspend/resume callback */
	ap_power_ev_init_callback(&cb, board_power_change,
				  AP_POWER_PRE_INIT |
					  AP_POWER_SHUTDOWN_COMPLETE);
	ap_power_ev_add_callback(&cb);
	return 0;
}
SYS_INIT(board_power_handler_init, APPLICATION, 1);
```

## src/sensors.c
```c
/* Copyright 2021 The Chromium OS Authors. All rights reserved.
 * Use of this source code is governed by a BSD-style license that can be
 * found in the LICENSE file.
 */

#include "chipset.h"
#include "common.h"
#include "keyboard_scan.h"

/* Lazor board specific sensor implementation */

#ifdef CONFIG_LID_ANGLE_UPDATE
void lid_angle_peripheral_enable(int enable)
{
	int chipset_in_s0 = chipset_in_state(CHIPSET_STATE_ON);

	if (enable) {
		keyboard_scan_enable(1, KB_SCAN_DISABLE_LID_ANGLE);
	} else {
		/*
		 * Ensure that the chipset is off before disabling the keyboard.
		 * When the chipset is on, the EC keeps the keyboard enabled and
		 * the AP decides whether to ignore input devices or not.
		 */
		if (!chipset_in_s0)
			keyboard_scan_enable(0, KB_SCAN_DISABLE_LID_ANGLE);
	}
}
#endif
```

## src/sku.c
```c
/* Copyright 2022 The ChromiumOS Authors
 * Use of this source code is governed by a BSD-style license that can be
 * found in the LICENSE file.
 */

#include "common.h"
#include "config.h"
#include "console.h"
#include "driver/ln9310.h"
#include "tcpm/ps8xxx_public.h"
#include "hooks.h"
#include "sku.h"
#include "system.h"
#include "util.h"

#define CPRINTS(format, args...) cprints(CC_USBCHARGE, format, ##args)
#define CPRINTF(format, args...) cprintf(CC_USBCHARGE, format, ##args)

static uint8_t sku_id;

enum board_model {
	LAZOR,
	LIMOZEEN,
	UNKNOWN,
};

static const char *const model_name[] = {
	"LAZOR",
	"LIMOZEEN",
	"UNKNOWN",
};

static enum board_model get_model(void)
{
	if (sku_id == 0 || sku_id == 1 || sku_id == 2 || sku_id == 3)
		return LAZOR;
	if (sku_id == 4 || sku_id == 5 || sku_id == 6)
		return LIMOZEEN;
	return UNKNOWN;
}

/* Read SKU ID from GPIO and initialize variables for board variants */
static void sku_init(void)
{
	sku_id = system_get_sku_id();
	CPRINTS("SKU: %u (%s)", sku_id, model_name[get_model()]);
}
DECLARE_HOOK(HOOK_INIT, sku_init, HOOK_PRIO_POST_I2C);

enum battery_cell_type board_get_battery_cell_type(void)
{
	switch (get_model()) {
	case LIMOZEEN:
		return BATTERY_CELL_TYPE_3S;
	default:
		return BATTERY_CELL_TYPE_UNKNOWN;
	}
}

int board_is_clamshell(void)
{
	return get_model() == LIMOZEEN;
}

__override uint16_t board_get_ps8xxx_product_id(int port)
{
	/*
	 * Lazor (SKU_ID: 0, 1, 2, 3) rev 3+ changes TCPC from PS8751 to
	 * PS8805.
	 *
	 * Limozeen (SKU_ID: 4, 5, 6) all-rev uses PS8805.
	 */
	if (get_model() == LAZOR && system_get_board_version() < 3)
		return PS8751_PRODUCT_ID;

	return PS8805_PRODUCT_ID;
}

int board_has_da9313(void)
{
	return get_model() == LAZOR;
}

int board_has_buck_ic(void)
{
	return get_model() == LIMOZEEN && system_get_board_version() >= 8;
}

int board_has_ln9310(void)
{
	return get_model() == LIMOZEEN && system_get_board_version() < 8;
}
```

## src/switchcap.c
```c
/* Copyright 2022 The Chromium OS Authors. All rights reserved.
 * Use of this source code is governed by a BSD-style license that can be
 * found in the LICENSE file.
 */

#include <zephyr/drivers/gpio.h>

#include "common.h"
#include "config.h"
#include "console.h"
#include "driver/ln9310.h"
#include "gpio/gpio_int.h"
#include "hooks.h"
#include "i2c.h"
#include "power/qcom.h"
#include "system.h"
#include "sku.h"

#define CPRINTS(format, args...) cprints(CC_I2C, format, ##args)
#define CPRINTF(format, args...) cprintf(CC_I2C, format, ##args)

/* LN9310 switchcap */
const struct ln9310_config_t ln9310_config = {
	.i2c_port = I2C_PORT_POWER,
	.i2c_addr_flags = LN9310_I2C_ADDR_0_FLAGS,
};

static void switchcap_init(void)
{
	if (board_has_da9313()) {
		CPRINTS("Use switchcap: DA9313");

		/*
		 * When the chip in power down mode, it outputs high-Z.
		 * Set pull-down to avoid floating.
		 */
		gpio_pin_configure_dt(GPIO_DT_FROM_NODELABEL(gpio_da9313_gpio0),
				      GPIO_INPUT | GPIO_PULL_DOWN);

		/*
		 * Configure DA9313 enable, push-pull output. Don't set the
		 * level here; otherwise, it will override its value and
		 * shutdown the switchcap when sysjump to RW.
		 */
		gpio_pin_configure_dt(GPIO_DT_FROM_NODELABEL(gpio_switchcap_on),
				      GPIO_OUTPUT);
	} else if (board_has_ln9310()) {
		CPRINTS("Use switchcap: LN9310");

		/* Enable interrupt for LN9310 */
		gpio_enable_dt_interrupt(
			GPIO_INT_FROM_NODELABEL(int_switchcap_pg));

		/*
		 * Configure LN9310 enable, open-drain output. Don't set the
		 * level here; otherwise, it will override its value and
		 * shutdown the switchcap when sysjump to RW.
		 *
		 * Note that the gpio.inc configures it GPIO_OUT_LOW. When
		 * sysjump to RW, will output push-pull a short period of
		 * time. As it outputs LOW, should be fine.
		 *
		 * This GPIO changes like:
		 * (1) EC boots from RO -> high-Z
		 * (2) GPIO init according to gpio.inc -> push-pull LOW
		 * (3) This function configures it -> open-drain HIGH
		 * (4) Power sequence turns on the switchcap -> open-drain LOW
		 * (5) EC sysjumps to RW
		 * (6) GPIO init according to gpio.inc -> push-pull LOW
		 * (7) This function configures it -> open-drain LOW
		 */
		gpio_pin_configure_dt(GPIO_DT_FROM_NODELABEL(gpio_switchcap_on),
				      GPIO_OUTPUT | GPIO_OPEN_DRAIN);

		/* Only configure the switchcap if not sysjump */
		if (!system_jumped_late()) {
			/*
			 * Deassert the enable pin, so the
			 * switchcap won't be enabled after the switchcap is
			 * configured from standby mode to switching mode.
			 */
			gpio_pin_set_dt(
				GPIO_DT_FROM_NODELABEL(gpio_switchcap_on), 0);
			ln9310_init();
		}
	} else if (board_has_buck_ic()) {
		CPRINTS("Use Buck IC");
	} else {
		CPRINTS("ERROR: No switchcap solution");
	}
}
DECLARE_HOOK(HOOK_INIT, switchcap_init, HOOK_PRIO_DEFAULT);

void board_set_switchcap_power(int enable)
{
	if (board_has_da9313()) {
		gpio_pin_set_dt(GPIO_DT_FROM_NODELABEL(gpio_switchcap_on),
				enable);
	} else if (board_has_ln9310()) {
		gpio_pin_set_dt(GPIO_DT_FROM_NODELABEL(gpio_switchcap_on),
				enable);
		ln9310_software_enable(enable);
	} else if (board_has_buck_ic()) {
		gpio_pin_set_dt(GPIO_DT_FROM_NODELABEL(gpio_vbob_en), enable);
	}
}

int board_is_switchcap_enabled(void)
{
	if (board_has_da9313() || board_has_ln9310())
		return gpio_pin_get_dt(
			GPIO_DT_FROM_NODELABEL(gpio_switchcap_on));

	/* Board has buck ic*/
	return gpio_pin_get_dt(GPIO_DT_FROM_NODELABEL(gpio_vbob_en));
}

int board_is_switchcap_power_good(void)
{
	if (board_has_da9313())
		return gpio_pin_get_dt(
			GPIO_DT_FROM_NODELABEL(gpio_da9313_gpio0));
	else if (board_has_ln9310())
		return ln9310_power_good();

	/* Board has buck ic no way to check POWER GOOD */
	return 1;
}
```

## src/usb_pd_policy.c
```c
/* Copyright 2022 The Chromium OS Authors. All rights reserved.
 * Use of this source code is governed by a BSD-style license that can be
 * found in the LICENSE file.
 */

#include <zephyr/drivers/gpio.h>

#include "charge_manager.h"
#include "chipset.h"
#include "console.h"
#include "system.h"
#include "usb_mux.h"
#include "usbc_ppc.h"
#include "util.h"

#define CPRINTS(format, args...) cprints(CC_USBCHARGE, format, ##args)
#define CPRINTF(format, args...) cprintf(CC_USBCHARGE, format, ##args)

int pd_check_vconn_swap(int port)
{
	/* In G3, do not allow vconn swap since PP5000 rail is off */
	return gpio_pin_get_dt(GPIO_DT_FROM_NODELABEL(gpio_en_pp5000_a));
}

static uint8_t vbus_en[CONFIG_USB_PD_PORT_MAX_COUNT];
#if CONFIG_USB_PD_PORT_MAX_COUNT == 1
static uint8_t vbus_rp[CONFIG_USB_PD_PORT_MAX_COUNT] = { TYPEC_RP_1A5 };
#else
static uint8_t vbus_rp[CONFIG_USB_PD_PORT_MAX_COUNT] = { TYPEC_RP_1A5,
							 TYPEC_RP_1A5 };
#endif

static void board_vbus_update_source_current(int port)
{
	/* Both port are controlled by PPC SN5S330. */
	ppc_set_vbus_source_current_limit(port, vbus_rp[port]);
	ppc_vbus_source_enable(port, vbus_en[port]);
}

void pd_power_supply_reset(int port)
{
	int prev_en;

	prev_en = vbus_en[port];

	/* Disable VBUS */
	vbus_en[port] = 0;
	board_vbus_update_source_current(port);

	/* Enable discharge if we were previously sourcing 5V */
	if (prev_en)
		pd_set_vbus_discharge(port, 1);

	/* notify host of power info change */
	pd_send_host_event(PD_EVENT_POWER_CHANGE);
}

int pd_set_power_supply_ready(int port)
{
	/* Disable charging */
	board_vbus_sink_enable(port, 0);

	pd_set_vbus_discharge(port, 0);

	/* Provide VBUS */
	vbus_en[port] = 1;
	board_vbus_update_source_current(port);

	/* notify host of power info change */
	pd_send_host_event(PD_EVENT_POWER_CHANGE);

	return EC_SUCCESS; /* we are ready */
}

int board_vbus_source_enabled(int port)
{
	return vbus_en[port];
}

__override void typec_set_source_current_limit(int port, enum tcpc_rp_value rp)
{
	vbus_rp[port] = rp;
	board_vbus_update_source_current(port);
}

int pd_snk_is_vbus_provided(int port)
{
	return tcpm_check_vbus_level(port, VBUS_PRESENT);
}

/* ----------------- Vendor Defined Messages ------------------ */
#ifdef CONFIG_USB_PD_ALT_MODE_DFP
__override int svdm_dp_config(int port, uint32_t *payload)
{
	int opos = pd_alt_mode(port, TCPCI_MSG_SOP, USB_SID_DISPLAYPORT);
	uint8_t pin_mode = get_dp_pin_mode(port);

	if (!pin_mode)
		return 0;

	/*
	 * Defer setting the usb_mux until HPD goes high, svdm_dp_attention().
	 * The AP only supports one DP phy. An external DP mux switches between
	 * the two ports. Should switch those muxes when it is really used,
	 * i.e. HPD high; otherwise, the real use case is preempted, like:
	 *  (1) plug a dongle without monitor connected to port-0,
	 *  (2) plug a dongle without monitor connected to port-1,
	 *  (3) plug a monitor to the port-1 dongle.
	 */

	payload[0] =
		VDO(USB_SID_DISPLAYPORT, 1, CMD_DP_CONFIG | VDO_OPOS(opos));
	payload[1] = VDO_DP_CFG(pin_mode, /* pin mode */
				1, /* DPv1.3 signaling */
				2); /* UFP connected */
	return 2;
};

__override void svdm_dp_post_config(int port)
{
	dp_flags[port] |= DP_FLAGS_DP_ON;
}

/**
 * Is the port fine to be muxed its DisplayPort lines?
 *
 * Only one port can be muxed to DisplayPort at a time.
 *
 * @param port	Port number of TCPC.
 * @return	1 is fine; 0 is bad as other port is already muxed;
 */
static int is_dp_muxable(int port)
{
	int i;

	for (i = 0; i < CONFIG_USB_PD_PORT_MAX_COUNT; i++)
		if (i != port) {
			if (usb_mux_get(i) & USB_PD_MUX_DP_ENABLED)
				return 0;
		}

	return 1;
}

__override int svdm_dp_attention(int port, uint32_t *payload)
{
	const struct gpio_dt_spec *hpd =
		GPIO_DT_FROM_NODELABEL(gpio_dp_hot_plug_det);
	int lvl = PD_VDO_DPSTS_HPD_LVL(payload[1]);
	int irq = PD_VDO_DPSTS_HPD_IRQ(payload[1]);
	int cur_lvl = gpio_pin_get_dt(hpd);
	mux_state_t mux_state;

	dp_status[port] = payload[1];

	if (!is_dp_muxable(port)) {
		/* TODO(waihong): Info user? */
		CPRINTS("p%d: The other port is already muxed.", port);
		return 0;
	}

	/*
	 * Initial implementation to handle HPD. Only the first-plugged port
	 * works, i.e. sending HPD signal to AP. The second-plugged port
	 * will be ignored.
	 *
	 * TODO(waihong): Continue the above case, if the first-plugged port
	 * is then unplugged, switch to the second-plugged port and signal AP?
	 */
	if (lvl) {
		/*
		 * Enable and switch the DP port selection mux to the
		 * correct port.
		 *
		 * TODO(waihong): Better to move switching DP mux to
		 * the usb_mux abstraction.
		 */
		gpio_pin_set_dt(GPIO_DT_FROM_NODELABEL(gpio_dp_mux_sel),
				port == 1);
		gpio_pin_set_dt(GPIO_DT_FROM_NODELABEL(gpio_dp_mux_oe_l), 0);

		/* Connect the SBU lines in PPC chip. */
		if (IS_ENABLED(CONFIG_USBC_PPC_SBU))
			ppc_set_sbu(port, 1);

		/*
		 * Connect the USB SS/DP lines in TCPC chip.
		 *
		 * When mf_pref not true, still use the dock muxing
		 * because of the board USB-C topology (limited to 2
		 * lanes DP).
		 */
		usb_mux_set(port, USB_PD_MUX_DOCK, USB_SWITCH_CONNECT,
			    polarity_rm_dts(pd_get_polarity(port)));
	} else {
		/* Disconnect the DP port selection mux. */
		gpio_pin_set_dt(GPIO_DT_FROM_NODELABEL(gpio_dp_mux_oe_l), 1);
		gpio_pin_set_dt(GPIO_DT_FROM_NODELABEL(gpio_dp_mux_sel), 0);

		/* Disconnect the SBU lines in PPC chip. */
		if (IS_ENABLED(CONFIG_USBC_PPC_SBU))
			ppc_set_sbu(port, 0);

		/* Disconnect the DP but keep the USB SS lines in TCPC chip. */
		usb_mux_set(port, USB_PD_MUX_USB_ENABLED, USB_SWITCH_CONNECT,
			    polarity_rm_dts(pd_get_polarity(port)));
	}

	if (chipset_in_state(CHIPSET_STATE_ANY_SUSPEND) && (irq || lvl))
		/*
		 * Wake up the AP.  IRQ or level high indicates a DP sink is now
		 * present.
		 */
		pd_notify_dp_alt_mode_entry(port);

	/* Configure TCPC for the HPD event, for proper muxing */
	mux_state = (lvl ? USB_PD_MUX_HPD_LVL : USB_PD_MUX_HPD_LVL_DEASSERTED) |
		    (irq ? USB_PD_MUX_HPD_IRQ : USB_PD_MUX_HPD_IRQ_DEASSERTED);
	usb_mux_hpd_update(port, mux_state);

	/* Signal AP for the HPD event, through GPIO to AP */
	if (irq & cur_lvl) {
		uint64_t now = get_time().val;
		/* Wait for the minimum spacing between IRQ_HPD if needed */
		if (now < svdm_hpd_deadline[port])
			usleep(svdm_hpd_deadline[port] - now);

		/* Generate IRQ_HPD pulse */
		gpio_pin_set_dt(hpd, 0);
		usleep(HPD_DSTREAM_DEBOUNCE_IRQ);
		gpio_pin_set_dt(hpd, 1);

		/* Set the minimum time delay (2ms) for the next HPD IRQ */
		svdm_hpd_deadline[port] =
			get_time().val + HPD_USTREAM_DEBOUNCE_LVL;
	} else if (irq & !lvl) {
		CPRINTF("ERR:HPD:IRQ&LOW\n");
		return 0;
	}
	gpio_pin_set_dt(hpd, lvl);
	/* Set the minimum time delay (2ms) for the next HPD IRQ */
	svdm_hpd_deadline[port] = get_time().val + HPD_USTREAM_DEBOUNCE_LVL;

	return 1;
}

__override void svdm_exit_dp_mode(int port)
{
	if (is_dp_muxable(port)) {
		/* Disconnect the DP port selection mux. */
		gpio_pin_set_dt(GPIO_DT_FROM_NODELABEL(gpio_dp_mux_oe_l), 1);
		gpio_pin_set_dt(GPIO_DT_FROM_NODELABEL(gpio_dp_mux_sel), 0);

		/* Signal AP for the HPD low event */
		usb_mux_hpd_update(port, USB_PD_MUX_HPD_LVL_DEASSERTED |
						 USB_PD_MUX_HPD_IRQ_DEASSERTED);
		gpio_pin_set_dt(GPIO_DT_FROM_NODELABEL(gpio_dp_hot_plug_det),
				0);
	}
}
#endif /* CONFIG_USB_PD_ALT_MODE_DFP */
```
